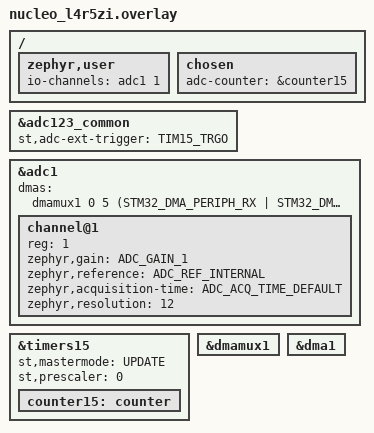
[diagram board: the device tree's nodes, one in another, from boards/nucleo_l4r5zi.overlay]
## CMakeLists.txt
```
cmake_minimum_required(VERSION 3.20.0)

find_package(Zephyr REQUIRED HINTS $ENV{ZEPHYR_BASE})
project(external_trigger)

target_sources(app PRIVATE src/main.c)
```

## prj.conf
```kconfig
CONFIG_ADC=y
CONFIG_ADC_ASYNC=y
CONFIG_ADC_STM32_DMA=y
CONFIG_COUNTER=y
CONFIG_LOG=y
```

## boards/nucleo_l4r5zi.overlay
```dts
/*
 * Copyright (c) 2026 Shontal Biton
 *
 * SPDX-License-Identifier: Apache-2.0
 */

/ {
	zephyr,user {
		io-channels = <&adc1 1>;
	};

	chosen {
		adc-counter = &counter15;
	};
};

&adc123_common {
	st,adc-ext-trigger = "TIM15_TRGO";
};

&adc1 {
	#address-cells = <1>;
	#size-cells = <0>;

	dmas = <&dmamux1 0 5 (STM32_DMA_PERIPH_RX | STM32_DMA_MEM_16BITS |
			      STM32_DMA_PERIPH_16BITS)>;
	dma-names = "dmamux";

	channel@1 {
		reg = <1>;
		zephyr,gain = "ADC_GAIN_1";
		zephyr,reference = "ADC_REF_INTERNAL";
		zephyr,acquisition-time = <ADC_ACQ_TIME_DEFAULT>;
		zephyr,resolution = <12>;
	};
};

&timers15 {
	st,mastermode = "UPDATE";
	st,prescaler = <0>;
	status = "okay";

	counter15: counter {
		status = "okay";
	};
};

&dmamux1 {
	status = "okay";
};

&dma1 {
	status = "okay";
};
```

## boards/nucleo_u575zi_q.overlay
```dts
/*
 * Copyright (c) 2026 Shontal Biton
 *
 * SPDX-License-Identifier: Apache-2.0
 */

/ {
	zephyr,user {
		io-channels = <&adc4 1>;
	};

	chosen {
		adc-counter = &counter15;
	};
};

&adc4_common {
	st,adc-ext-trigger = "TIM15_TRGO";
};

&adc4 {
	#address-cells = <1>;
	#size-cells = <0>;

	dmas = <&gpdma1 1 1 (STM32_DMA_PERIPH_RX | STM32_DMA_MEM_16BITS | STM32_DMA_PERIPH_16BITS)>;
	dma-names = "gpdma";

	channel@1 {
		reg = <1>;
		zephyr,gain = "ADC_GAIN_1";
		zephyr,reference = "ADC_REF_INTERNAL";
		zephyr,acquisition-time = <ADC_ACQ_TIME_DEFAULT>;
		zephyr,resolution = <12>;
	};
};

&timers15 {
	st,mastermode = "UPDATE";
	st,prescaler = <0>;
	status = "okay";

	counter15: counter {
		status = "okay";
	};
};
```

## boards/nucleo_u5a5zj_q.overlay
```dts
/*
 * Copyright (c) 2026 Shontal Biton
 *
 * SPDX-License-Identifier: Apache-2.0
 */

/ {
	zephyr,user {
		io-channels = <&adc1 1>;
	};

	chosen {
		adc-counter = &counter15;
	};
};

&adc12_common {
	st,adc-ext-trigger = "TIM15_TRGO";
};

&adc1 {
	#address-cells = <1>;
	#size-cells = <0>;

	dmas = <&gpdma1 0 0 (STM32_DMA_PERIPH_RX | STM32_DMA_MEM_16BITS | STM32_DMA_PERIPH_16BITS)>;
	dma-names = "gpdma";

	channel@1 {
		reg = <1>;
		zephyr,gain = "ADC_GAIN_1";
		zephyr,reference = "ADC_REF_INTERNAL";
		zephyr,acquisition-time = <ADC_ACQ_TIME_DEFAULT>;
		zephyr,resolution = <12>;
	};
};

&timers15 {
	st,mastermode = "UPDATE";
	st,prescaler = <0>;
	status = "okay";

	counter15: counter {
		status = "okay";
	};
};
```

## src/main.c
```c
/*
 * Copyright (c) 2026 Shontal Biton
 *
 * SPDX-License-Identifier: Apache-2.0
 */

#include <zephyr/drivers/adc.h>
#include <zephyr/drivers/counter.h>
#include <zephyr/logging/log.h>

LOG_MODULE_REGISTER(main, 4);

#define SAMPLING_RATE 8000
#define NUM_SAMPLES   16000

enum adc_action sample_end_event(const struct device *dev, const struct adc_sequence *sequence,
				 uint16_t sampling_index)
{
	LOG_DBG("Finished sampling for 2 seconds");
	LOG_HEXDUMP_INF(sequence->buffer, 20, "Buffer values are: ");

	return ADC_ACTION_CONTINUE;
}

uint16_t samples_buffer[NUM_SAMPLES] = {0};

int main(void)
{
	const struct device *timer = DEVICE_DT_GET(DT_CHOSEN(adc_counter));
	const struct adc_dt_spec channel = ADC_DT_SPEC_GET(DT_PATH(zephyr_user));
	const struct counter_top_cfg timer_cfg = {
		.ticks = (counter_get_frequency(timer) / SAMPLING_RATE),
	};
	const struct adc_sequence_options options = {
		.callback = sample_end_event,
		.extra_samplings = NUM_SAMPLES - 1,
	};
	struct adc_sequence seq = {
		.buffer = samples_buffer,
		.buffer_size = sizeof(samples_buffer),
		.options = &options,
	};
	int err;

	err = adc_sequence_init_dt(&channel, &seq);
	if (err) {
		LOG_ERR("Failed to init sequence");
		return err;
	}

	err = counter_start(timer);
	if (err) {
		LOG_ERR("Failed to start timer with error code: %d", err);
		return err;
	}

	err = counter_set_top_value(timer, &timer_cfg);
	if (err) {
		LOG_ERR("Failed to set timer configuration");
		return err;
	}

	err = adc_read_async_dt(&channel, &seq, NULL);
	if (err) {
		LOG_ERR("Failed to start reading");
		return err;
	}

	return 0;
}
```
